# AM13E23219 register map
Vendor: Texas Instruments; File version: 1.0
CPU: CM33 r0p1, little endian, MPU, FPU, VTOR, 4 interrupt priority bits
Registers are 32-bit, read-write, reset 0x0 unless marked. A register's access mark holds for its fields unless they carry their own. Offsets are from the block's base; [hi:lo] are bit positions; {n}, {i} and the like mark numbered series.

## GSC — GSC module
Base 0x40046000
0x1004 SPC_ATTRIBVIOLP_CONFIG — SRAM Privilege Access Attribute Violation Configuration Register
  [0] PRIVVIOL — Privilege access to non-privilege SRAM
0x1014 PPC_ATTRIBVIOLP_CONFIG — Peripheral Privilege Access Attribute Violation Configuration Register
  [0] PRIVVIOL — Privilege access to non-privilege Peripheral
0x1024 FPC_ATTRIBVIOLP_CONFIG — Flash Privilege Access Attribute Violation Configuration Register
  [0] PRIVVIOL — Privilege access to non-privilege Flash
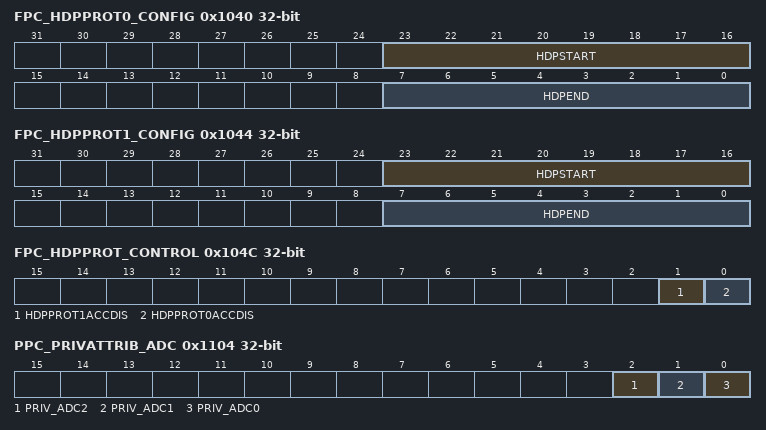
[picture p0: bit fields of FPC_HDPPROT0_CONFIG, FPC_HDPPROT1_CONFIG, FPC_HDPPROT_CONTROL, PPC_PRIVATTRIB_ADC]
0x1040 FPC_HDPPROT0_CONFIG — Flash Hide Protection for Bank0 Configuration Register
  [23:16] HDPSTART — HDPPROT0 start sector number
  [7:0] HDPEND — HDPPROT0 end sector number
0x1044 FPC_HDPPROT1_CONFIG — Flash Hide Protection for Bank1 Configuration Register
  [23:16] HDPSTART — HDPPROT1 start sector number
  [7:0] HDPEND — HDPPROT1 end sector number
0x104C FPC_HDPPROT_CONTROL — Flash Hide Protection Control Register
  [1] HDPPROT1ACCDIS — HDP region-1 enable
  [0] HDPPROT0ACCDIS — HDP region-0 enable
0x1050 FPC_HDPEN_CONTROL — Flash Hide Protection Enable Control Register
  [0] HDPEN — HDP mode enable
0x1104 PPC_PRIVATTRIB_ADC — Peripheral Privilege Access ADC
  [2] PRIV_ADC2 — Privilege access for ADC2
  [1] PRIV_ADC1 — Privilege access for ADC1
  [0] PRIV_ADC0 — Privilege access for ADC0
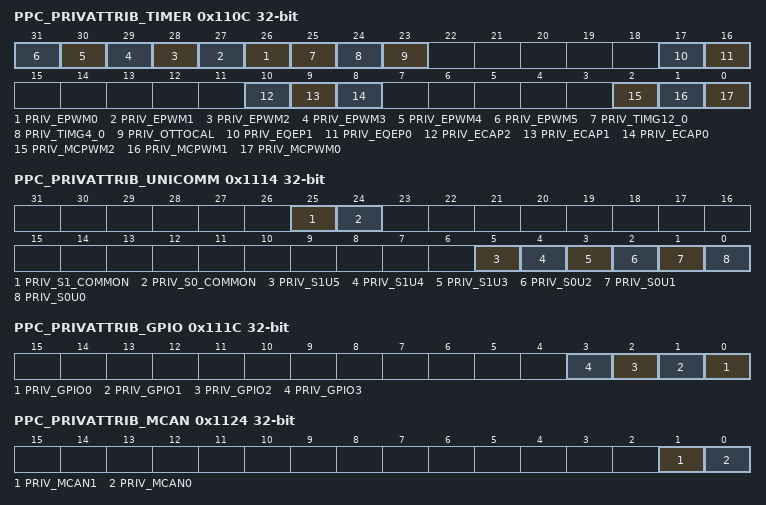
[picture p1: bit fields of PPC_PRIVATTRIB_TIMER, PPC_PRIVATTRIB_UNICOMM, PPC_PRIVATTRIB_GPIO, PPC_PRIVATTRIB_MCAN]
0x110C PPC_PRIVATTRIB_TIMER — Peripheral Privilege Access Timer
  [n+26] PRIV_EPWM{n} (n=0..5) — Privilege access for EPWM{n}
  [25] PRIV_TIMG12_0 — Privilege access for TIMG12_0
  [24] PRIV_TIMG4_0 — Privilege access for TIMG4_0
  [23] PRIV_OTTOCAL — Privilege access for OTTOCAL
  [17] PRIV_EQEP1 — Privilege access for EQEP1
  [16] PRIV_EQEP0 — Privilege access for EQEP0
  [10] PRIV_ECAP2 — Privilege access for ECAP2
  [9] PRIV_ECAP1 — Privilege access for ECAP1
  [8] PRIV_ECAP0 — Privilege access for ECAP0
  [2] PRIV_MCPWM2 — Privilege access for MCPWM2
  [1] PRIV_MCPWM1 — Privilege access for MCPWM1
  [0] PRIV_MCPWM0 — Privilege access for MCPWM0
0x1114 PPC_PRIVATTRIB_UNICOMM — Peripheral Privilege Access UniComm
  [25] PRIV_S1_COMMON — Privilege access for UniComm S1 common region
  [24] PRIV_S0_COMMON — Privilege access for UniComm S0 common region
  [5] PRIV_S1U5 — Privilege access for UniComm S1U5
  [4] PRIV_S1U4 — Privilege access for UniComm S1U4
  [3] PRIV_S1U3 — Privilege access for UniComm S1U3
  [2] PRIV_S0U2 — Privilege access for UniComm S0U2
  [1] PRIV_S0U1 — Privilege access for UniComm S0U1
  [0] PRIV_S0U0 — Privilege access for UniComm S0U0
0x111C PPC_PRIVATTRIB_GPIO — Peripheral Privilege Access GPIO
  [n] PRIV_GPIO{n} (n=0..3) — Privilege access for GPIO{n}
0x1124 PPC_PRIVATTRIB_MCAN — Peripheral Privilege Access CAN
  [1] PRIV_MCAN1 — Privilege access for MCAN1
  [0] PRIV_MCAN0 — Privilege access for MCAN0
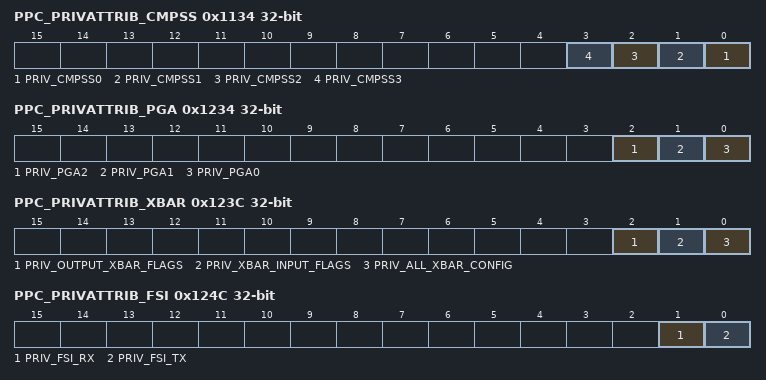
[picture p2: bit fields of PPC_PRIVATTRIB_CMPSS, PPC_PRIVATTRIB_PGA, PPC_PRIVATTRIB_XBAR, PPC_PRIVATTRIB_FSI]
0x1134 PPC_PRIVATTRIB_CMPSS — Peripheral Privilege Access CMPSS
  [n] PRIV_CMPSS{n} (n=0..3) — Privilege access for CMPSS{n}
0x113C PPC_PRIVATTRIB_WDT — Peripheral Privilege Access Watchdog
  [0] PRIV_WWDT — Privilege access for Windowed Watchdog
0x114C PPC_PRIVATTRIB_CRC — Peripheral Privilege Access CRC
  [0] PRIV_CRC — Privilege access for CRC
0x1154 PPC_PRIVATTRIB_AES — Peripheral Privilege Access AES
  [0] PRIV_AES — Privilege access for AES
0x116C PPC_PRIVATTRIB_IOMUX — Peripheral Privilege Access IOMUX
  [0] PRIV_IOMUX — Privilege access for IOMUX
0x1184 PPC_PRIVATTRIB_DEBUGSS — Peripheral Privilege Access DEBUGSS
  [0] PRIV_DEBUGSS — Privilege access for DEBUGSS
0x1194 PPC_PRIVATTRIB_KEYSTORECTL — Peripheral Privilege Access KEYSTORECTL
  [0] PRIV_KEYSTORECTL — Privilege access for KEYSTORECTL
0x119C PPC_PRIVATTRIB_EAM — Peripheral Privilege Access EAM
  [0] PRIV_EAM — Privilege access for EAM
0x11AC PPC_PRIVATTRIB_FRIREGS — Peripheral Privilege Access FRIREGS
  [0] PRIV_FRIREGS — Privilege access for FRIREGS
0x11B4 PPC_PRIVATTRIB_MEMCFG — Peripheral Privilege Access MEMCFG
  [0] PRIV_MEMCFG — Privilege access for MEMCFG
0x120C PPC_PRIVATTRIB_SYSCTL — Peripheral Privilege Access System Control
  [0] PRIV_SYSCTL — Privilege access for SYSCTL
0x1214 PPC_PRIVATTRIB_DMA — Peripheral Privilege Access DMA
  [0] PRIV_DMA — Privilege access for DMA
0x121C PPC_PRIVATTRIB_GSC — Peripheral Privilege Access GSC
  [0] PRIV_GSC — Privilege access for GSC
0x1224 PPC_PRIVATTRIB_COPROC — Peripheral Privilege Access Co-processor
  [0] PRIV_TINIE — Privilege access for TINIE
0x1234 PPC_PRIVATTRIB_PGA — Peripheral Privilege Access PGA
  [2] PRIV_PGA2 — Privilege access for PGA2
  [1] PRIV_PGA1 — Privilege access for PGA1
  [0] PRIV_PGA0 — Privilege access for PGA0
0x123C PPC_PRIVATTRIB_XBAR — Peripheral Privilege Access XBAR
  [2] PRIV_OUTPUT_XBAR_FLAGS — Privilege access for OUTPUT_XBAR_FLAGS
  [1] PRIV_XBAR_INPUT_FLAGS — Privilege access for XBAR_INPUT_FLAGS
  [0] PRIV_ALL_XBAR_CONFIG — Privilege access for ALL_XBAR_CONFIG
0x1244 PPC_PRIVATTRIB_ETHERCAT — Peripheral Privilege Access ETHERCAT
  [0] PRIV_ETHERCAT — Privilege access for ETHERCAT
0x124C PPC_PRIVATTRIB_FSI — Peripheral Privilege Access FSI
  [1] PRIV_FSI_RX — Privilege access for FSI_RX
  [0] PRIV_FSI_TX — Privilege access for FSI_TX
0x1254 PPC_PRIVATTRIB_SDFM — Peripheral Privilege Access SDFM
  [0] PRIV_SDFM — Privilege access for SDFM
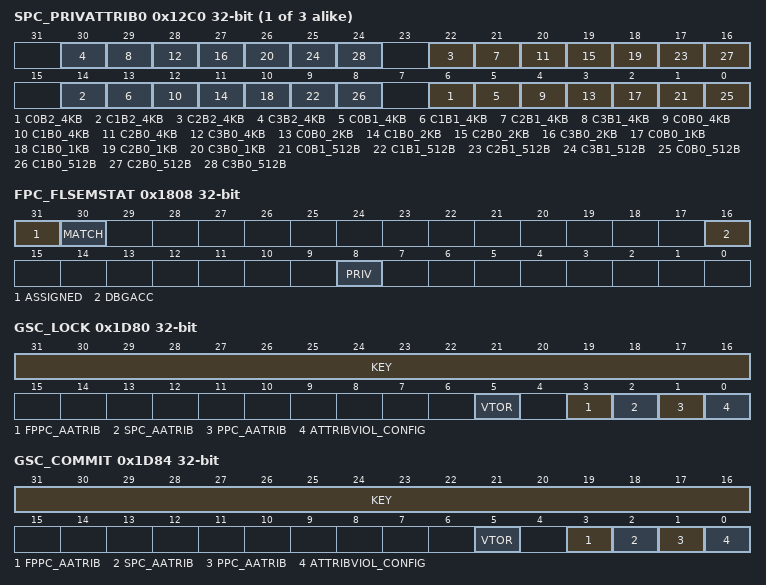
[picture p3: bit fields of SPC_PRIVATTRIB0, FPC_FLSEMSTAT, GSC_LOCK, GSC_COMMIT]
{0x12C0+4i} SPC_PRIVATTRIB{i} (i=0..2) — SRAM Privilege Attribute-{i} Register
  [8n+6] C{n}B2_4KB (n=0..3) — privilege access for third 4KB in page-{n}
  [8n+5] C{n}B1_4KB (n=0..3) — privilege access for second 4KB in page-{n}
  [8n+4] C{n}B0_4KB (n=0..3) — privilege access for first 4KB in page-{n}
  [8n+3] C{n}B0_2KB (n=0..3) — privilege access for 2KB in page-{n}
  [8n+2] C{n}B0_1KB (n=0..3) — privilege access for 1KB in page-{n}
  [8n+1] C{n}B1_512B (n=0..3) — privilege access for second 512 byte in page-{n}
  [8n] C{n}B0_512B (n=0..3) — privilege access for first 512 byte in page-{n}
0x1400 FPC_PRIVATTRIBA0 access not given — Flash Privilege Attribute Register A0
0x1404 FPC_PRIVATTRIBA1 access not given — Flash Privilege Attribute Register A1
0x1408 FPC_PRIVATTRIBB0 — Flash Privilege Attribute Register B0
  [15:4] PRIV_PAGE — Privilege access for higher sectors of Bank0
0x140C FPC_PRIVATTRIBB1 — Flash Privilege Attribute Register B1
  [15:4] PRIV_PAGE — Privilege access for higher sectors of Bank1
0x1600 FPC_WEPROTA0 access not given — Flash Write Protect Attribute Register A0
0x1604 FPC_WEPROTA1 access not given — Flash Write Protect Attribute Register A1
0x1608 FPC_WEPROTB0 — Flash Write Protect Attribute Register B0
  [15:4] WEPROT_PAGE — Erase/program protection for higher sectors of Flash Bank0
0x160C FPC_WEPROTB1 — Flash Write Protect Attribute Register B1
  [15:4] WEPROT_PAGE — Erase/program protection for higher sectors of Flash Bank1
0x1800 FPC_FLSEMREQ — Flash semaphore request register
  [0] REQ — Request Semaphore Ownership
0x1804 FPC_FLSEMCLR — Flash semaphore release register
  [0] CLR — Release Semaphore Ownership
0x1808 FPC_FLSEMSTAT ro — Flash semaphore statys registers
  [31] ASSIGNED — Assigned Flag
  [30] MATCH — Match Status Bit
  [16] DBGACC — Semaphore debug access
  [8] PRIV — Semaphore Privilage attribute
0x1B84 VTOR_NS access not given — Non - Secure Vector Table Offset Register
0x1D80 GSC_LOCK access per field — GSC Lock configuration register
  [31:16] KEY wo — Key which must be written for the write to take effect.
  [5] VTOR rw — Register lock configuration
  [3] FPPC_AATRIB rw — Register lock configuration
  [2] SPC_AATRIB rw — Register lock configuration
  [1] PPC_AATRIB rw — Register lock configuration
  [0] ATTRIBVIOL_CONFIG rw — Register lock configuration
0x1D84 GSC_COMMIT access per field — GSC commit configuration register
  [31:16] KEY wo — Key which must be written for the write to take effect.
  [5] VTOR rw — Register lock committed
  [3] FPPC_AATRIB rw — Register lock committed
  [2] SPC_AATRIB rw — Register lock committed
  [1] PPC_AATRIB rw — Register lock committed
  [0] ATTRIBVIOL_CONFIG rw — Register lock committed
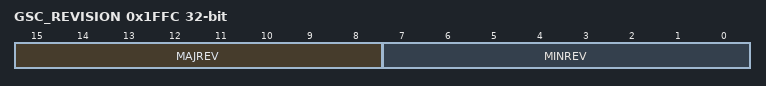
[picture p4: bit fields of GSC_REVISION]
0x1FFC GSC_REVISION ro
  [15:8] MAJREV — Major Revision Number
  [7:0] MINREV — Minor Revision Number
